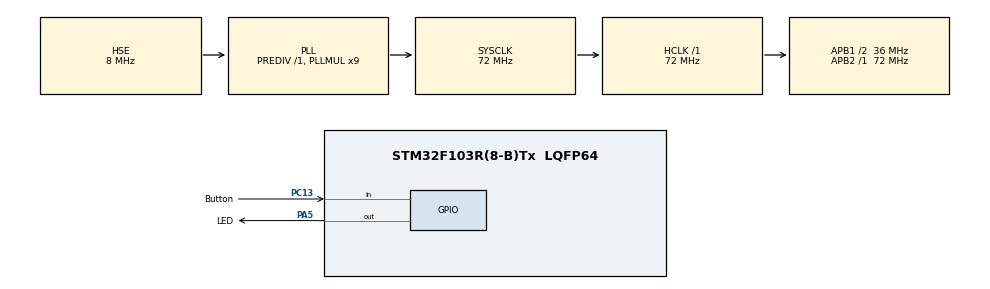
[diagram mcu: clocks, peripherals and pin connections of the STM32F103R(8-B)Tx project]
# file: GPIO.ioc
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Mcu.Family=STM32F1
Mcu.Name=STM32F103R(8-B)Tx
Mcu.Package=LQFP64
NVIC.PriorityGroup=NVIC_PRIORITYGROUP_4
PA13.Mode=Serial_Wire
PA13.Signal=SYS_JTMS-SWDIO
PA14.Mode=Serial_Wire
PA14.Signal=SYS_JTCK-SWCLK
PA5.GPIO_Label=LED
PA5.GPIO_ModeDefaultOutputPP=GPIO_MODE_OUTPUT_PP
PA5.GPIO_PuPd=GPIO_NOPULL
PA5.Signal=GPIO_Output
PC13-TAMPER-RTC.GPIO_Label=Button
PC13-TAMPER-RTC.Signal=GPIO_Input
PD0-OSC_IN.Mode=HSE-External-Oscillator
PD0-OSC_IN.Signal=RCC_OSC_IN
PD1-OSC_OUT.Mode=HSE-External-Oscillator
PD1-OSC_OUT.Signal=RCC_OSC_OUT
ProjectManager.HeapSize=0x200
ProjectManager.StackSize=0x400
ProjectManager.TargetToolchain=Makefile
RCC.AHBFreq_Value=72000000
RCC.APB1CLKDivider=RCC_HCLK_DIV2
RCC.APB1Freq_Value=36000000
RCC.APB1TimFreq_Value=72000000
RCC.APB2Freq_Value=72000000
RCC.APB2TimFreq_Value=72000000
RCC.HCLKFreq_Value=72000000
RCC.PLLMUL=RCC_PLL_MUL9
RCC.PLLSourceVirtual=RCC_PLLSOURCE_HSE
RCC.SYSCLKFreq_VALUE=72000000
RCC.SYSCLKSource=RCC_SYSCLKSOURCE_PLLCLK
RCC.USBFreq_Value=72000000
board=custom

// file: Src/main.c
/* USER CODE BEGIN Header */
/**
  ******************************************************************************
  * @file           : main.c
  * @brief          : Main program body
  ******************************************************************************
  * @attention
  *
  * <h2><center>&copy; Copyright (c) 2019 STMicroelectronics.
  * All rights reserved.</center></h2>
  *
  * This software component is licensed by ST under BSD 3-Clause license,
  * the "License"; You may not use this file except in compliance with the
  * License. You may obtain a copy of the License at:
  *                        opensource.org/licenses/BSD-3-Clause
  *
  ******************************************************************************
  */
/* USER CODE END Header */
#include "main.h"
#include "gpio.h"

void SystemClock_Config(void);

int main(void)
{

  /* MCU Configuration--------------------------------------------------------*/

  /* Reset of all peripherals, Initializes the Flash interface and the Systick. */
  HAL_Init();

  /* Configure the system clock */
  SystemClock_Config();

  /* Initialize all configured peripherals */
  MX_GPIO_Init();

  /* Infinite loop */
  while (1)
  {

    /* USER CODE BEGIN 3 */

    // 逐个控制LED闪烁
    HAL_GPIO_WritePin(LED_GPIO_Port, LED_Pin, GPIO_PIN_SET);   //点亮LED
    HAL_Delay(1000);                                           // 等待1�?
    HAL_GPIO_WritePin(LED_GPIO_Port, LED_Pin, GPIO_PIN_RESET); //熄灭LED
    HAL_Delay(2000);                                           //等待2�?
    HAL_GPIO_WritePin(LED_GPIO_Port, LED_Pin, GPIO_PIN_SET);   //点亮LED
    HAL_Delay(1000);                                           //等待1�?

    // 连续闪烁10�?
    for (uint8_t i = 0; i < 20; i++) //闪烁十次代表变化了二十次电平
    {
      HAL_GPIO_TogglePin(LED_GPIO_Port, LED_Pin); //变化引脚上电�?
      HAL_Delay(100);                             //等待0.1秒�?�每两次闪烁间时间为0.1秒，故频率为5Hz
    }
    HAL_GPIO_WritePin(LED_GPIO_Port, LED_Pin, GPIO_PIN_RESET); //熄灭LED

    // 等待按键输入三次
    for (uint8_t i = 0; i < 3; i++)
    {
      // 等待按键按下
      do
      {
        while (HAL_GPIO_ReadPin(Button_GPIO_Port, Button_Pin) == GPIO_PIN_SET) //等待电平变高
          ;
        HAL_Delay(1); //延时消抖

      } while (HAL_GPIO_ReadPin(Button_GPIO_Port, Button_Pin) == GPIO_PIN_SET); //第二次检�?

      // 等待按键松开
      do
      {
        while (HAL_GPIO_ReadPin(Button_GPIO_Port, Button_Pin) == GPIO_PIN_RESET) //等待电平变低
          ;
        HAL_Delay(1); //延时等待

      } while (HAL_GPIO_ReadPin(Button_GPIO_Port, Button_Pin) == GPIO_PIN_RESET); //第二次检�?
    }
  }
  /* USER CODE END 3 */
}

void SystemClock_Config(void)
{
  RCC_OscInitTypeDef RCC_OscInitStruct = {0};
  RCC_ClkInitTypeDef RCC_ClkInitStruct = {0};

  /** Initializes the RCC Oscillators according to the specified parameters
  * in the RCC_OscInitTypeDef structure.
  */
  RCC_OscInitStruct.OscillatorType = RCC_OSCILLATORTYPE_HSE;
  RCC_OscInitStruct.HSEState = RCC_HSE_ON;
  RCC_OscInitStruct.HSEPredivValue = RCC_HSE_PREDIV_DIV1;
  RCC_OscInitStruct.HSIState = RCC_HSI_ON;
  RCC_OscInitStruct.PLL.PLLState = RCC_PLL_ON;
  RCC_OscInitStruct.PLL.PLLSource = RCC_PLLSOURCE_HSE;
  RCC_OscInitStruct.PLL.PLLMUL = RCC_PLL_MUL9;
  if (HAL_RCC_OscConfig(&RCC_OscInitStruct) != HAL_OK)
  {
    Error_Handler();
  }
  /** Initializes the CPU, AHB and APB buses clocks
  */
  RCC_ClkInitStruct.ClockType = RCC_CLOCKTYPE_HCLK|RCC_CLOCKTYPE_SYSCLK
                              |RCC_CLOCKTYPE_PCLK1|RCC_CLOCKTYPE_PCLK2;
  RCC_ClkInitStruct.SYSCLKSource = RCC_SYSCLKSOURCE_PLLCLK;
  RCC_ClkInitStruct.AHBCLKDivider = RCC_SYSCLK_DIV1;
  RCC_ClkInitStruct.APB1CLKDivider = RCC_HCLK_DIV2;
  RCC_ClkInitStruct.APB2CLKDivider = RCC_HCLK_DIV1;

  if (HAL_RCC_ClockConfig(&RCC_ClkInitStruct, FLASH_LATENCY_2) != HAL_OK)
  {
    Error_Handler();
  }
}

void Error_Handler(void)
{
}

/************************ (C) COPYRIGHT STMicroelectronics *****END OF FILE****/
